# RockChip_RK3588 register map
Vendor: RockChip Electronics Co., Ltd.; Series: RK3588; File version: 0.1
Registers are 32-bit, read-write, no defined reset value unless marked. A register's access mark holds for its fields unless they carry their own. Offsets are from the block's base; [hi:lo] are bit positions; {n}, {i} and the like mark numbered series; 'fields as' and 'values as' point back to an identical list.

## GRF_DDR01
Base 0xFD59C000
Same registers: GRF_DDR23 0xFD59D000
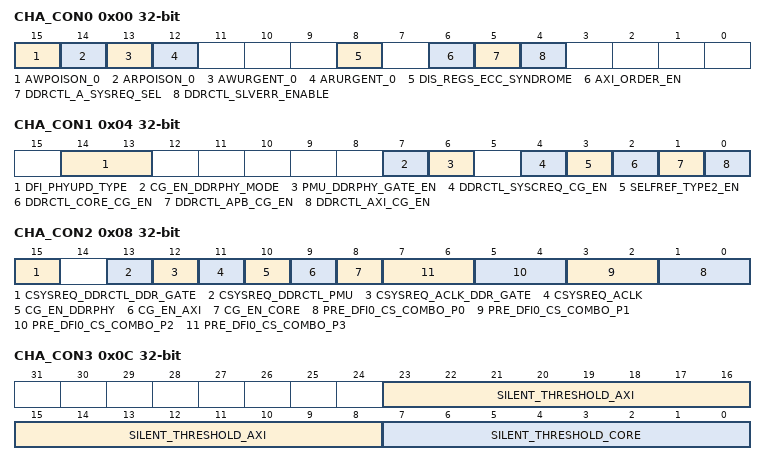
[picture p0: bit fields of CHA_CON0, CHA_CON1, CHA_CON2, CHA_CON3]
0x00 CHA_CON0 — DDR CHA Control Register 0
  [15] AWPOISON_0 — DDRCTL AXI write address poison
    1=ENABLE (Enable poison on write command); 0=DISABLE
  [14] ARPOISON_0 — DDRCTL AXI read address poison
    1=ENABLE (Enable poison on read command); 0=DISABLE
  [13] AWURGENT_0 — DDRCTL AXI write address urgent
    1=URGENT (Current aw command is urgent); 0=NOT_URGENT
  [12] ARURGENT_0 — DDRCTL AXI read address urgent
    1=URGENT (Current ar command is urgent); 0=NOT_URGENT
  [8] DIS_REGS_ECC_SYNDROME — Value of dis_regs_ecc_syndrome. Signal used to hide the value of ECCCSYN* and ECCUSYN* registers for security purposes. When this value is set to 1, reading registers ECCCSYN*/ECCUSYN* returns value 0 always, otherwise it returns appropriate value. If this feature is not used, this port can be tied to 0. The value of dis_regs_ecc_syndrome signal cannot change outside of reset(presetn=0 && core_ddrc_core_rstn=0).
  [6] AXI_ORDER_EN — Enable preserve DDRCTL AXI cmd order counter. Please keep default 1'b1 all the time.
    1=ENABLE; 0=DISABLE
  [5] DDRCTL_A_SYSREQ_SEL — DDRCTL AXI hardware low power request by PMU
    1=PMU (DDRCTL AXI hardware low power request is driven by PMU.); 0=NOT_PMU (DDRCTL AXI hardware low power request is not driven by PMU.)
  [4] DDRCTL_SLVERR_ENABLE — DDRCTL slave APB error response enable
    0=DISABLE (Disable DDRCTL from responding error); 1=ENABLE (Enable DDRCTL from responding error)
0x04 CHA_CON1 — DDR CHA Control Register 1
  [14:13] DFI_PHYUPD_TYPE — This signal is the DFI PHY-initiated update. This signal indicates which one of the four types of PHY update times is being requested by the dfi_phyupd_req signal. The valid values are as follows:
    {v}=TPHYUPD_TYPE{v} (v=0..3)
  [7] CG_EN_DDRPHY_MODE — DDRPHY ctrl_phy_cg_en gate control mode
    1=Ctrl_phy_cg_en is set to 1'b1 to gate DDRPHY internal clock according to the status of DDRPHY dfi_phyupd_req or dfi_phymstr_active or when DDRCTL AXI aclk and core clk are both gated; 0=Ctrl_phy_cg_en is set to 1'b1 to gate DDRPHY internal clock according to the status of DDRPHY dfi_phyupd_req or dfi_phymstr_active
  [6] PMU_DDRPHY_GATE_EN — Enable PMU auto gate DDRPHY clock function If it is set 1'b1, ctrl_phy_cg_en of DDRPHY will be controlled by PMU.
    1=ENABLE; 0=DISABLE
  [4] DDRCTL_SYSCREQ_CG_EN — DDRCTL core clk gate enable during SR-PD
    1=ENABLE; 0=DISABLE
  [3] SELFREF_TYPE2_EN — DDRCTL selfrefresh type for auto gate
    0=ONLY_SELF_REFRESH (SDRAM is in SR-Powerdown (LPDDR4/5), which was caused by automatic self refresh only. If retry is enabled, this guarantees SRE command is executed correctly without parity error.); 1=ANY (SDRAM is in SR-Powerdown (LPDDR4/5), which was not caused solely under automatic self refresh control. It could have been caused by hardware low power interface and/or software (PWRCTL.selfref_sw). If retry is enabled, this guarantees SRE command is executed correctly without parity error.)
  [2] DDRCTL_CORE_CG_EN — DDRCTL core clk gate enable
    1=ENABLE (Enable DDRCTL core clk auto gate); 0=DISABLE
  [1] DDRCTL_APB_CG_EN — DDRCTL APB pclk gate enable
    1=ENABLE (Enable DDRCTL pclk auto gate); 0=DISABLE
  [0] DDRCTL_AXI_CG_EN — DDRCTL AXI aclk gate enable
    1=ENABLE (Enable DDRCTL AXI auto gate); 0=DISABLE
0x08 CHA_CON2 — DDR CHA Control Register 2
  [15] CSYSREQ_DDRCTL_DDR_GATE — DDRCTL core hardware low power request by hardware gate control logic
    1=BY_HW (DDRCTL core hardware low power request is driven by hardware gate control logic.); 0=NOT_BY_HW (DDRCTL core hardware low power request is not driven by hardware gate control logic.)
  [13] CSYSREQ_DDRCTL_PMU — DDRCTL core hardware low power request by PMU
    1=BY_PMU (DDRCTL core hardware low power request is driven by PMU.); 0=NOT_BY_PMU (DDRCTL core hardware low power request is not driven by PMU.)
  [12] CSYSREQ_ACLK_DDR_GATE — DDRCTL AXI hardware low power request by hardware gate control logic
    1=BY_HW (DDRCTL AXI hardware low power request is driven by hardware gate control logic.); 0=NOT_BY_HW (DDRCTL AXI hardware low power request is not driven by hardware gate control logic.)
  [11] CSYSREQ_ACLK — DDRCTL AXI hardware low power request by GRF
    1=BY_DDR_GRF (DDRCTL AXI hardware low power request is driven by DDR01_GRF or DDR23_GRF.); 0=NOT_BY_DDR_GRF (DDRCTL AXI hardware low power request is not driven by DDR01_GRF or DDR23_GRF.)
  [10] CG_EN_DDRPHY — Enable DDRPHY ctrl_phy_cg_en auto gate function
    1=ENABLE; 0=DISABLE
  [9] CG_EN_AXI — Enable DDRCTL hardware mode AXI aclk auto gate function
    1=ENABLE; 0=DISABLE
  [8] CG_EN_CORE — Enable DDRCTL hardware mode core clk auto gate function
    1=ENABLE; 0=DISABLE
  [2n+1:2n] PRE_DFI0_CS_COMBO_P{n} (n=0..3) — These grf bits drive dfi_cs_P{n}
0x0C CHA_CON3 — DDR CHA Control Register 3
  [23:8] SILENT_THRESHOLD_AXI — Control after how many silent cycles, auto gate will gate DDRCTL aclk
  [7:0] SILENT_THRESHOLD_CORE — Control after how many silent cycles, auto gate will gate DDRCTL core clk.
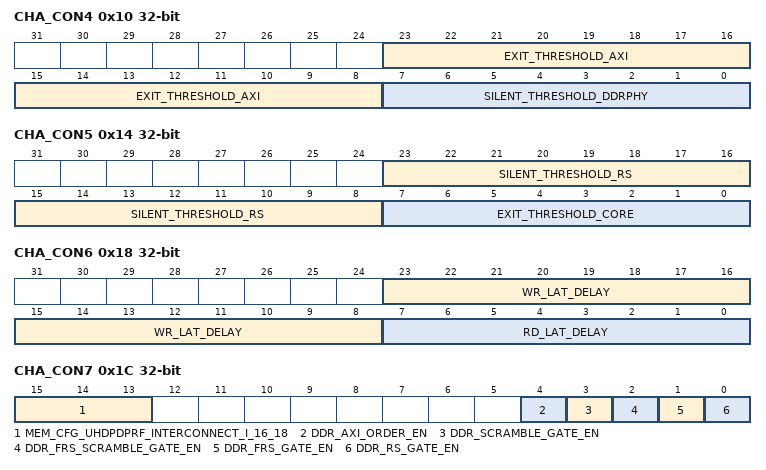
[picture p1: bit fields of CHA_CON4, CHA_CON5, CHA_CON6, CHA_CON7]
0x10 CHA_CON4 — DDR CHA Control Register 4
  [23:8] EXIT_THRESHOLD_AXI — Exit time from gating DDRCTL aclk
  [7:0] SILENT_THRESHOLD_DDRPHY — Control after how many silent cycles, auto gate will enable ctrl_phy_cg_en to gate DDRPHY clock.
0x14 CHA_CON5 — DDR CHA Control Register 5
  [23:8] SILENT_THRESHOLD_RS — Control after how many silent cycles, auto gate will gate rs bridge clock Rs bridge is a module to add one pipeline for AXI bus.
  [7:0] EXIT_THRESHOLD_CORE — Exit time from gating DDRCTL core clk
0x18 CHA_CON6 — DDR CHA Control Register 6
  [23:8] WR_LAT_DELAY — Control dfi_lp_data_req high level time during write
  [7:0] RD_LAT_DELAY — Control dfi_lp_data_req high level time during read
0x1C CHA_CON7 — DDR CHA Control Register 7
  [15:13] MEM_CFG_UHDPDPRF_INTERCONNECT_I_16_18 — Control the mem_cfg bit 16-18 for uhdpdprf for interconnect. bit 0: TESTRWM
  [4] DDR_AXI_ORDER_EN — Enable preserve DDR scheduler AXI cmd order counter. Please keep default 1'b1 all the time.
    1=ENABLE; 0=DISABLE
  [3] DDR_SCRAMBLE_GATE_EN — Enable auto gate ddr scramble clock between DDR scheduler and DDRCTL
    1=ENABLE; 0=DISABLE
  [2] DDR_FRS_SCRAMBLE_GATE_EN — Enable auto gate ddr scramble frs clock between DDR scheduler and DDRCTL
    1=ENABLE; 0=DISABLE
  [1] DDR_FRS_GATE_EN — Enable auto gate ddr frs clock between DDR scheduler and DDRCTL
    1=ENABLE; 0=DISABLE
  [0] DDR_RS_GATE_EN — Enable auto gate ddr rs clock between DDR scheduler and DDRCTL
    1=ENABLE; 0=DISABLE
0x20 CHA_CON8 — DDR CHA Control Register 8
  [15:0] MEM_CFG_UHDPDPRF_INTERCONNECT_I_0_15 — Control the mem_cfg bit 0-15 for uhdpdprf for interconnect. bit 0: TEST1 bit 1: TEST_RNM bit 4~2: RM bit 5: WMDA bit 7: LS
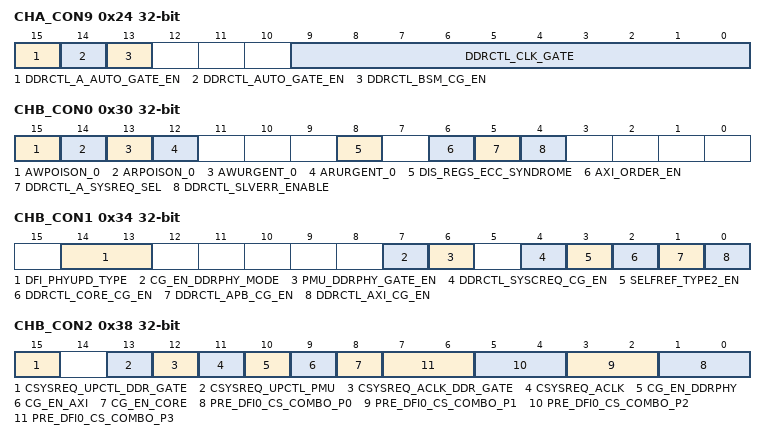
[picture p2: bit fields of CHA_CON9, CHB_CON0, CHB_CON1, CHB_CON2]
0x24 CHA_CON9 — DDR CHA Control Register 9
  [all] fields
    1=ENABLE; 0=DISABLE
  [15] DDRCTL_A_AUTO_GATE_EN — Enable DDRCTL core hardware low power gate control logic
  [14] DDRCTL_AUTO_GATE_EN — Enable DDRCTL AXI hardware low power gate control logic
  [13] DDRCTL_BSM_CG_EN — Enable DDRCTL bsm clock gate function
  [9:0] DDRCTL_CLK_GATE — Each bit will enable an internal auto gate function in DDRCTL
0x30 CHB_CON0 — DDR CHB Control Register 0
  [15] AWPOISON_0 — DDRCTL AXI write address poison
    1=ENABLE (Enable poison on write command); 0=DISABLE
  [14] ARPOISON_0 — DDRCTL AXI read address poison
    1=ENABLE (Enable poison on read command); 0=DISABLE
  [13] AWURGENT_0 — DDRCTL AXI write address urgent
    1=URGENT (Current aw command is urgent); 0=NOT_URGENT
  [12] ARURGENT_0 — DDRCTL AXI read address urgent
    1=Current ar command is urgent; 0=NOT_URGENT
  [8] DIS_REGS_ECC_SYNDROME — Value of dis_regs_ecc_syndrome. Signal used to hide the value of ECCCSYN* and ECCUSYN* registers for security purposes. When this value is set to 1, reading registers ECCCSYN*/ECCUSYN* returns value 0 always, otherwise it returns appropriate value. If this feature is not used, this port can be tied to 0. The value of dis_regs_ecc_syndrome signal cannot change outside of reset(presetn=0 && core_ddrc_core_rstn=0).
  [6] AXI_ORDER_EN — Enable preserve DDRCTL AXI cmd order counter
    1=ENABLE; 0=Disable Please keep default 1 all the time
  [5] DDRCTL_A_SYSREQ_SEL — DDRCTL AXI hardware low power request by PMU
    1=BY_PMU (DDRCTL AXI hardware low power request is driven by PMU.); 0=NOT_BY_PMU (DDRCTL AXI hardware low power request is not driven by PMU.)
  [4] DDRCTL_SLVERR_ENABLE — DDRCTL slave APB error response enable
    values as CHA_CON0.DDRCTL_SLVERR_ENABLE
0x34 CHB_CON1 — DDR CHB Control Register 1
  [14:13] DFI_PHYUPD_TYPE — This signal is the DFI PHY-initiated update. This signal indicates which one of the four types of PHY update times is being requested by the dfi_phyupd_req signal. The valid values are as follows:
    {v}=TPHYUPD_TYPE{v} (v=0..3)
  [7] CG_EN_DDRPHY_MODE — DDRPHY ctrl_phy_cg_en gate control mode
    values as CHA_CON1.CG_EN_DDRPHY_MODE
  [6] PMU_DDRPHY_GATE_EN — Enable PMU auto gate DDRPHY clock function If it is set 1'b1, ctrl_phy_cg_en of DDRPHY will be controlled by PMU.
    1=ENABLE; 0=DISABLE
  [4] DDRCTL_SYSCREQ_CG_EN — DDRCTL core clk gate enable during SR-PD
    1=ENABLE; 0=DISABLE
  [3] SELFREF_TYPE2_EN — DDRCTL selfrefresh type for auto gate
    0=SR_AUTO_ONLY (SDRAM is in SR-Powerdown (LPDDR4/5), which was caused by automatic self refresh only. If retry is enabled, this guarantees SRE command is executed correctly without parity error.); 1=SR_BY_ANY (SDRAM is in SR-Powerdown (LPDDR4/5), which was not caused solely under automatic self refresh control. It could have been caused by hardware low power interface and/or software (PWRCTL.selfref_sw). If retry is enabled, this guarantees SRE command is executed correctly without parity error.)
  [2] DDRCTL_CORE_CG_EN — DDRCTL core clk gate enable
    1=ENABLE (Enable DDRCTL core clk auto gate); 0=DISABLE
  [1] DDRCTL_APB_CG_EN — DDRCTL APB pclk gate enable
    1=ENABLE (Enable DDRCTL pclk auto gate); 0=DISABLE
  [0] DDRCTL_AXI_CG_EN — DDRCTL AXI aclk gate enable
    1=ENABLE (Enable DDRCTL AXI auto gate); 0=DISABLE
0x38 CHB_CON2 — DDR CHB Control Register 2
  [15] CSYSREQ_UPCTL_DDR_GATE — DDRCTL core hardware low power request by hardware gate control logic
    values as CHA_CON2.CSYSREQ_DDRCTL_DDR_GATE
  [13] CSYSREQ_UPCTL_PMU — DDRCTL core hardware low power request by PMU
    values as CHA_CON2.CSYSREQ_DDRCTL_PMU
  [12] CSYSREQ_ACLK_DDR_GATE — DDRCTL AXI hardware low power request by hardware gate control logic
    values as CHA_CON2.CSYSREQ_ACLK_DDR_GATE
  [11] CSYSREQ_ACLK — DDRCTL AXI hardware low power request by GRF
    values as CHA_CON2.CSYSREQ_ACLK
  [10] CG_EN_DDRPHY — Enable DDRPHY ctrl_phy_cg_en auto gate function
    1=ENABLE; 0=DISABLE
  [9] CG_EN_AXI — Enable DDRCTL hardware mode AXI aclk auto gate function
    1=ENABLE; 0=DISABLE
  [8] CG_EN_CORE — Enable DDRCTL hardware mode core clk auto gate function
    1=ENABLE; 0=DISABLE
  [2n+1:2n] PRE_DFI0_CS_COMBO_P{n} (n=0..3) — These grf bits drive dfi_cs_P{n}
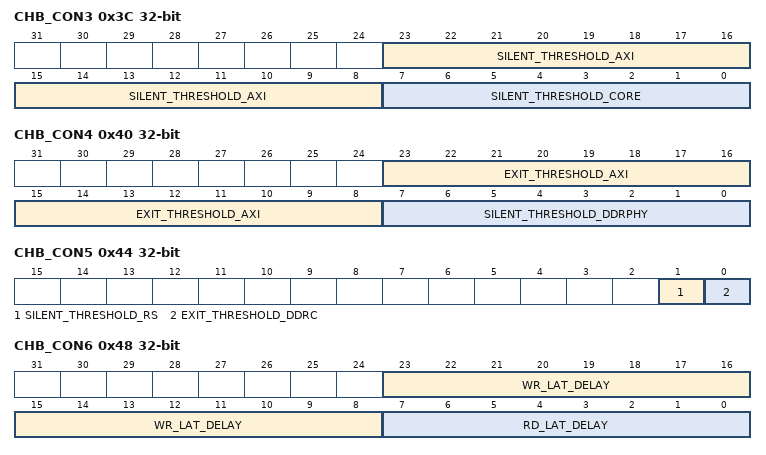
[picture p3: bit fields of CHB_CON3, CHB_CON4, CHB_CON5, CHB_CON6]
0x3C CHB_CON3 — DDR CHB Control Register 3
  fields as CHA_CON3
0x40 CHB_CON4 — DDR CHB Control Register 4
  fields as CHA_CON4
0x44 CHB_CON5 — DDR CHB Control Register 5
  [1] SILENT_THRESHOLD_RS — Control after how many silent cycles, auto gate will gate rs bridge clock Rs bridge is a module to add one pipeline for AXI bus.
  [0] EXIT_THRESHOLD_DDRC — Exit time from gating DDRCTL core clk
0x48 CHB_CON6 — DDR CHB Control Register 6
  fields as CHA_CON6
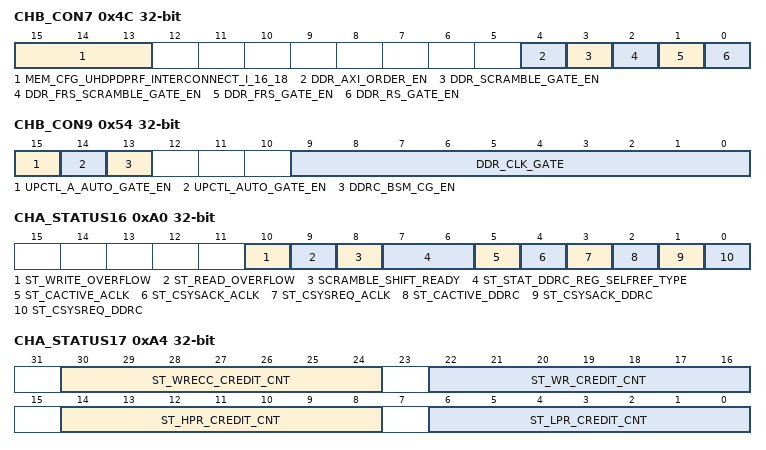
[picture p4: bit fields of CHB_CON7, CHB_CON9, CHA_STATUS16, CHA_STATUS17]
0x4C CHB_CON7 — DDR CHB Control Register 7
  fields as CHA_CON7
0x50 CHB_CON8 — DDR CHB Control Register 8
  fields as CHA_CON8
0x54 CHB_CON9 — DDR CHB Control Register 9
  [all] fields
    1=ENABLE; 0=DISABLE
  [15] UPCTL_A_AUTO_GATE_EN — Enable DDRCTL core hardware low power gate control logic
  [14] UPCTL_AUTO_GATE_EN — Enable DDRCTL AXI hardware low power gate control logic
  [13] DDRC_BSM_CG_EN — Enable DDRCTL bsm clock gate function
  [9:0] DDR_CLK_GATE — Each bit will enable an internal auto gate function in DDRCTL
0x60 CHA_STATUS0 — DDR CHA Status Register 0
  [31:0] ST_MRR_DATA0 ro — MRR data from DDRCTL
0xA0 CHA_STATUS16 — DDR CHA Status Register 16
  [10] ST_WRITE_OVERFLOW ro — DDR scramble write overflow status
    0=NOT_OVERFLOW; 1=OVERFLOW
  [9] ST_READ_OVERFLOW ro — DDR scramble read overflow status
    0=NOT_OVERFLOW; 1=OVERFLOW
  [8] SCRAMBLE_SHIFT_READY ro — Scramble shift ready status
    0=NOT_READY; 1=READY
  [7:6] ST_STAT_DDRC_REG_SELFREF_TYPE ro — DDRCTL selfrefresh type status Flags if SR-Powerdown is entered and if it was under automatic self refresh control only or not.
    0=NOT_SR_PD (SDRAM is not in SR-Powerdown.); 1=SR_BY_PHY (SDRAM is in self refresh, which was caused by PHY master request.); 2=SR_BY_ANY (SDRAM is in SR-Powerdown, which was not caused solely under automatic self refresh control.); 3=SR_AUTO_ONLY (SDRAM is in SR-Powerdown, which was caused by automatic self refresh only.)
  [5] ST_CACTIVE_ACLK ro — DDRCTL aclk cactive status
    0=NOT_ACTIVE; 1=ACTIVE
  [4] ST_CSYSACK_ACLK ro — DDRCTL aclk csysack status
    1=DOC_BUG_ACK (Low power request is acknowledged.); 0=DOC_BUG_NAK (Low power request is not acknowledged.)
  [3] ST_CSYSREQ_ACLK ro — DDRCTL aclk csysreq status
    0=LOW_POWER_REQUEST; 1=NO_LOW_POWER_REQUEST
  [2] ST_CACTIVE_DDRC ro — DDRCTL core cactive status
    0=NOT_ACTIVE; 1=ACTIVE
  [1] ST_CSYSACK_DDRC ro — DDRCTL core low power ack status
    values as ST_CSYSACK_ACLK
  [0] ST_CSYSREQ_DDRC ro — DDRCTL core low power request status
    0=LOW_POWER_REQUEST; 1=NO_LOW_POWER_REQUEST
0xA4 CHA_STATUS17 — DDR CHA Status Register 17
  [30:24] ST_WRECC_CREDIT_CNT ro — DDRCTL wrecc credit count
  [22:16] ST_WR_CREDIT_CNT ro — DDRCTL wr credit count
  [14:8] ST_HPR_CREDIT_CNT ro — DDRCTL hpr credit count
  [6:0] ST_LPR_CREDIT_CNT ro — DDRCTL lpr credit count
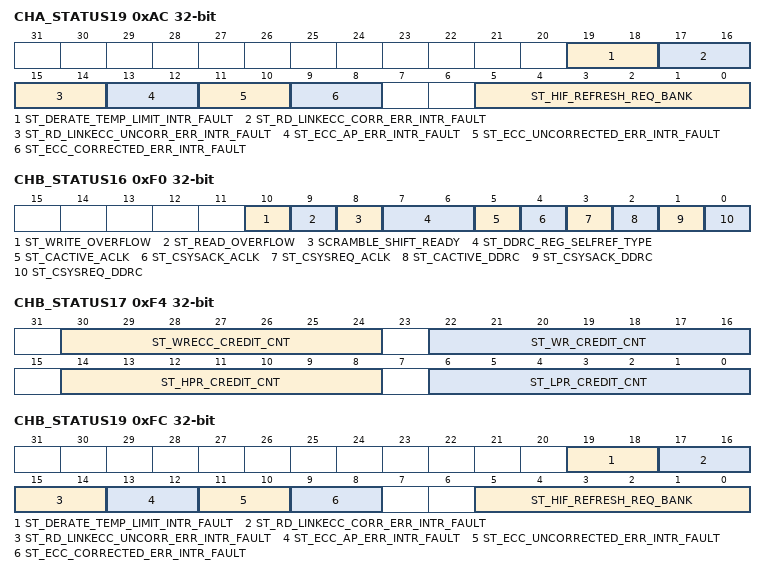
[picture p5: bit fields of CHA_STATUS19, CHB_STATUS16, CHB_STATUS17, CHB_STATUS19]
0xAC CHA_STATUS19 — DDR CHA Status Register 19
  [19:18] ST_DERATE_TEMP_LIMIT_INTR_FAULT ro — This signal is the derate temperature limit fault. This is a version of derate_temp_limit_intr, which can not be disabled or forced via a register. It is a 2-bit antivalent signal with encoding as follows:
    1=NO_FAULT; 2=FAULT_DETECTED
  [17:16] ST_RD_LINKECC_CORR_ERR_INTR_FAULT ro — This signal is the read Link-ECC corrected error fault. This is a version of rd_linkecc_corr_err_intr which can not be disabled or forced through a register. It is a 2-bit antivalent signal with encoding of
    1=NO_FAULT; 2=FAULT_DETECTED
  [15:14] ST_RD_LINKECC_UNCORR_ERR_INTR_FAULT ro — This signal is the read Link-ECC uncorrected error fault. This is a version of rd_linkecc_uncorr_err_intr, which can not be disabled or forced through a register. It is a 2-bit antivalent signal with encoding as follows:
    1=NO_FAULT; 2=FAULT_DETECTED
  [13:12] ST_ECC_AP_ERR_INTR_FAULT ro — This signal is the ECC address protection fault. This is a version of ecc_ap_err_intr which can not be disabled or forced through a register. It is a 2-bit antivalent signal with encoding as follows:
    1=NO_FAULT; 2=FAULT_DETECTED
  [11:10] ST_ECC_UNCORRECTED_ERR_INTR_FAULT ro — This signal is the ECC uncorrected error fault. This is a version of ecc_uncorrected_err_intr which can not be disabled or forced through a register. It is a 2-bit antivalent signal with encoding as follows:
    1=NO_FAULT; 2=FAULT_DETECTED
  [9:8] ST_ECC_CORRECTED_ERR_INTR_FAULT ro — This signal is the ECC corrected error fault. This is a version of ecc_corrected_err_intr which can not be disabled or forced through register. It is a 2-bit antivalent signal with encoding as follows:
    1=NO_FAULT; 2=FAULT_DETECTED
  [5:0] ST_HIF_REFRESH_REQ_BANK ro — This signal indicates the next bank that is refreshed (channel 1); for multi-rank configurations, the bank number is reported independently for each rank, and the information for all ranks is concatenated to form this signal.
0xB0 CHB_STATUS0 — DDR CHB Status Register 0
  [31:0] ST_MRR_DATA0 ro — MRR data from DDRCTL
0xF0 CHB_STATUS16 — DDR CHB Status Register 16
  [10] ST_WRITE_OVERFLOW ro — DDR scramble write overflow status
    0=NOT_OVERFLOW; 1=OVERFLOW
  [9] ST_READ_OVERFLOW ro — DDR scramble read overflow status
    0=NOT_OVERFLOW; 1=OVERFLOW
  [8] SCRAMBLE_SHIFT_READY ro — Scramble shift ready status
    0=NOT_READY; 1=READY
  [7:6] ST_DDRC_REG_SELFREF_TYPE ro — DDRCTL selfrefresh type status Flags if SR-Powerdown is entered and if it was under automatic self refresh control only or not.
    values as CHA_STATUS16.ST_STAT_DDRC_REG_SELFREF_TYPE
  [5] ST_CACTIVE_ACLK ro — DDRCTL aclk cactive status
    0=NOT_ACTIVE; 1=ACTIVE
  [4] ST_CSYSACK_ACLK ro — DDRCTL aclk csysack status
    values as CHA_STATUS16.ST_CSYSACK_ACLK
  [3] ST_CSYSREQ_ACLK ro — DDRCTL aclk csysreq status
    0=LOW_POWER_REQUEST; 1=NO_LOW_POWER_REQUEST
  [2] ST_CACTIVE_DDRC ro — DDRCTL core cactive status
    0=NOT_ACTIVE; 1=ACTIVE
  [1] ST_CSYSACK_DDRC ro — DDRCTL core low power ack status
    1=DOC_BUG_ACK (Low power request is acknowledged); 0=DOC_BUG_NAK (Low power request is not acknowledged)
  [0] ST_CSYSREQ_DDRC ro — DDRCTL core low power request status
    0=LOW_POWER_REQUEST; 1=NO_LOW_POWER_REQUEST
0xF4 CHB_STATUS17 — DDR CHB Status Register 17
  fields as CHA_STATUS17
0xFC CHB_STATUS19 — DDR CHB Status Register 19
  fields as CHA_STATUS19
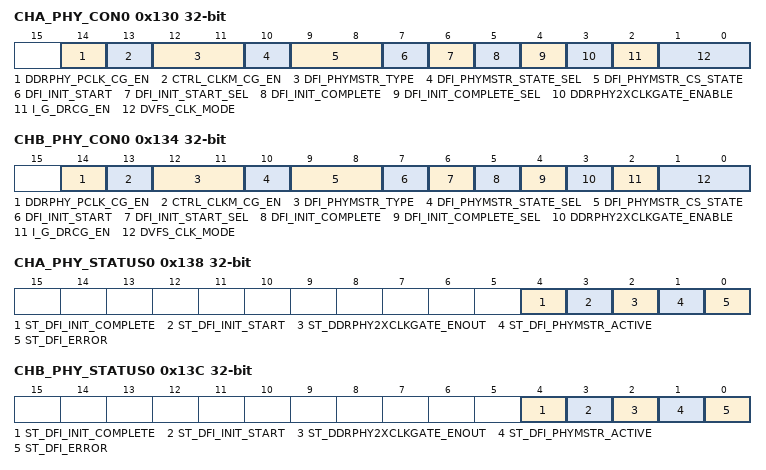
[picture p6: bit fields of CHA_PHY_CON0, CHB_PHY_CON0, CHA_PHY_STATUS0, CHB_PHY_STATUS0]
0x130 CHA_PHY_CON0 — DDRPHY CHA Control Register 0
  [14] DDRPHY_PCLK_CG_EN — DDRPHY APB pclk clock gate enable
    1=ENABLE; 0=DISABLE
  [13] CTRL_CLKM_CG_EN — DDRPHY master DLL clock gating enable.
    0=DISABLED (DDRPHY master DLL clock gating is disabled.); 1=ENABLED (DDRPHY master DLL clock gating is enabled.)
  [12:11] DFI_PHYMSTR_TYPE — Value of dfi_phymstr_type
  [10] DFI_PHYMSTR_STATE_SEL — Value of dfi_phymastr_state_sel
  [9:8] DFI_PHYMSTR_CS_STATE — Value of dfi_phymstr_cs_state
  [7] DFI_INIT_START — Value of dfi_init_start
  [6] DFI_INIT_START_SEL — DDRPHY dfi_init_start select
    0=BY_DDRCTL (DDRPHY dfi_init_start is driven by DDRCTL); 1=BY_DDR_GRF (DDRPHY dfi_init_start is driven by DDR01_GRF or DDR23_GRF)
  [5] DFI_INIT_COMPLETE — Value of dfi_init_complete
  [4] DFI_INIT_COMPLETE_SEL — DDRCTL dfi_init_complete select
    0=BY_DDRPHY (DDRCTL dfi_init_complete is driven by DDRPHY); 1=BY_DDR_GRF (DDRCTL dfi_init_complete is driven by DDR01_GRF or DDR23_GRF)
  [3] DDRPHY2XCLKGATE_ENABLE — Root clock gating control of DDRPHY. It controls clock gating of clk_phy2x. Set this pin to low to enable clock gating for clk_phy2x. For normal operation and DDRPHY test mode, this pin should be high. Root clock gating should be enabled while dfi_dram_clk_disable=1'b1.
  [2] I_G_DRCG_EN — Dynamic regional clock gating control for DDRPHY. DRCG refers to clock gating controlled by pcl_pd field in LP_CON0 register.
    1=ENABLED (DRCG is enabled regardless of pcl_pd field); 0=BY_PCL_PD (DRCG will be controlled by pcl_pd field in LP_CON0)
  [1:0] DVFS_CLK_MODE — DVFS mode select for clock mode between DFI clock and DFI PHY clock. This signal controls which DVFS register sets will be used after frequency change.
    0=NORMAL; 1=DVFS0; 2=DVFS1
0x134 CHB_PHY_CON0 — DDRPHY CHB Control Register 0
  fields as CHA_PHY_CON0
0x138 CHA_PHY_STATUS0 — DDRPHY CHA Status Register 0
  [4] ST_DFI_INIT_COMPLETE ro — Dfi_init_complete status
  [3] ST_DFI_INIT_START ro — Dfi_init_start status
  [2] ST_DDRPHY2XCLKGATE_ENOUT ro — Status of ddrphy2xclkgate_enout signal. This is a feed-through signal of ddrphy2xclkgate_enable. This signal can be monitored to get the status of ddrphy2xclkgate_enable signal.
  [1] ST_DFI_PHYMSTR_ACTIVE ro — DDRPHY phymstr_active status
  [0] ST_DFI_ERROR ro — DDRPHY dfi error status Indicates that the DDRPHY has detected an error condition such as read FIFO pointer error, conflict DLL update and wrdata and conflict DLL update and rddata.
0x13C CHB_PHY_STATUS0 — DDRPHY CHB Status Register 1
  fields as CHA_PHY_STATUS0
0x140 CON0 — DDR Control Register 0
  [23:0] MEM_CFG_HSDPRF_DDRCTL — Control the mem_cfg bit 0-21 for hsdprf for DDRCTL. bit 0: TEST1A bit 1: TEST_RNMA bit 5~2: RMA bit 6: WMDA bit 8: LS bit 14~13: RA bit 17: TEST1B bit 21~18: RMB
